# BL808 register map
File version: 0.1
Registers are access not given, no defined reset value unless marked. A register's access mark holds for its fields unless they carry their own. Offsets are from the block's base; [hi:lo] are bit positions; {n}, {i} and the like mark numbered series.

## CCI
Base 0x20008000
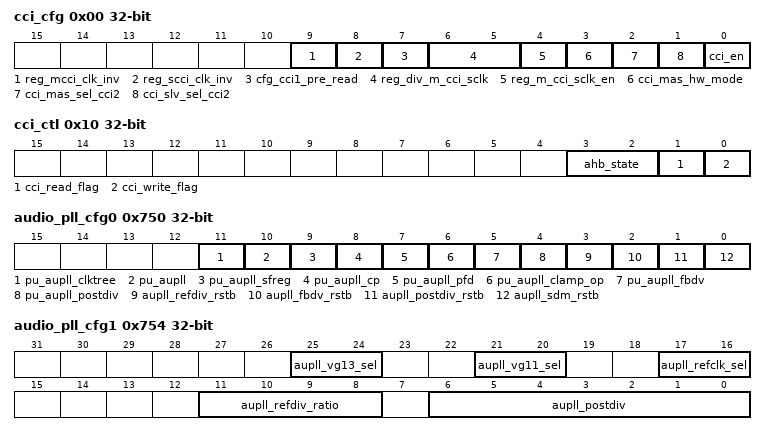
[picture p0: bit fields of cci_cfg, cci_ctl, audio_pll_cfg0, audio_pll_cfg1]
0x00 cci_cfg
  [9] reg_mcci_clk_inv rw, [8] reg_scci_clk_inv rw, [7] cfg_cci1_pre_read rw, [6:5] reg_div_m_cci_sclk rw, [4] reg_m_cci_sclk_en rw, [3] cci_mas_hw_mode rw, [2] cci_mas_sel_cci2 rw, [1] cci_slv_sel_cci2 rw, [0] cci_en rw
0x04 cci_addr rw
  [31:0] apb_cci_addr
0x08 cci_wdata rw
  [31:0] apb_cci_wdata
0x0C cci_rdata ro
  [31:0] apb_cci_rdata
0x10 cci_ctl
  [3:2] ahb_state ro, [1] cci_read_flag ro, [0] cci_write_flag ro
0x750 audio_pll_cfg0
  [11] pu_aupll_clktree rw, [10] pu_aupll rw, [9] pu_aupll_sfreg rw, [8] pu_aupll_cp rw, [7] pu_aupll_pfd rw, [6] pu_aupll_clamp_op rw, [5] pu_aupll_fbdv rw, [4] pu_aupll_postdiv rw, [3] aupll_refdiv_rstb rw, [2] aupll_fbdv_rstb rw, [1] aupll_postdiv_rstb rw, [0] aupll_sdm_rstb rw
0x754 audio_pll_cfg1
  [25:24] aupll_vg13_sel rw, [21:20] aupll_vg11_sel rw, [17:16] aupll_refclk_sel rw, [11:8] aupll_refdiv_ratio rw, [6:0] aupll_postdiv rw
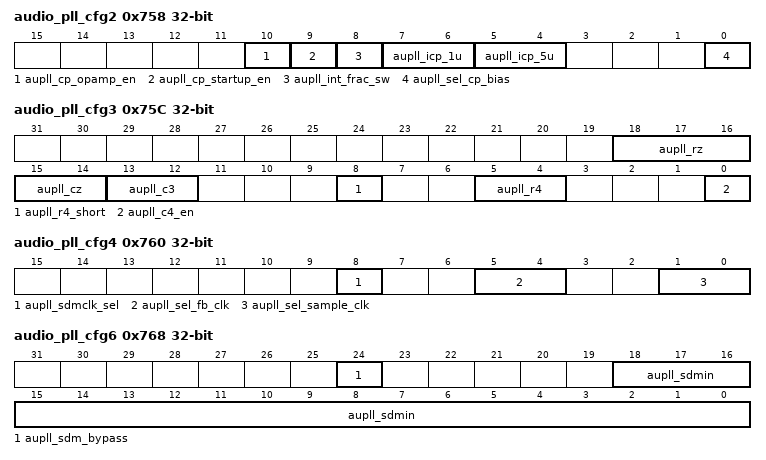
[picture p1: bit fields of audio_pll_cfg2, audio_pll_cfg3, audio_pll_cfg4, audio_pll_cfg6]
0x758 audio_pll_cfg2
  [10] aupll_cp_opamp_en rw, [9] aupll_cp_startup_en rw, [8] aupll_int_frac_sw rw, [7:6] aupll_icp_1u rw, [5:4] aupll_icp_5u rw, [0] aupll_sel_cp_bias rw
0x75C audio_pll_cfg3
  [18:16] aupll_rz rw, [15:14] aupll_cz rw, [13:12] aupll_c3 rw, [8] aupll_r4_short rw, [5:4] aupll_r4 rw, [0] aupll_c4_en rw
0x760 audio_pll_cfg4
  [8] aupll_sdmclk_sel rw, [5:4] aupll_sel_fb_clk rw, [1:0] aupll_sel_sample_clk rw
0x764 audio_pll_cfg5
  [2:0] aupll_vco_speed rw
0x768 audio_pll_cfg6
  [24] aupll_sdm_bypass rw, [18:0] aupll_sdmin rw
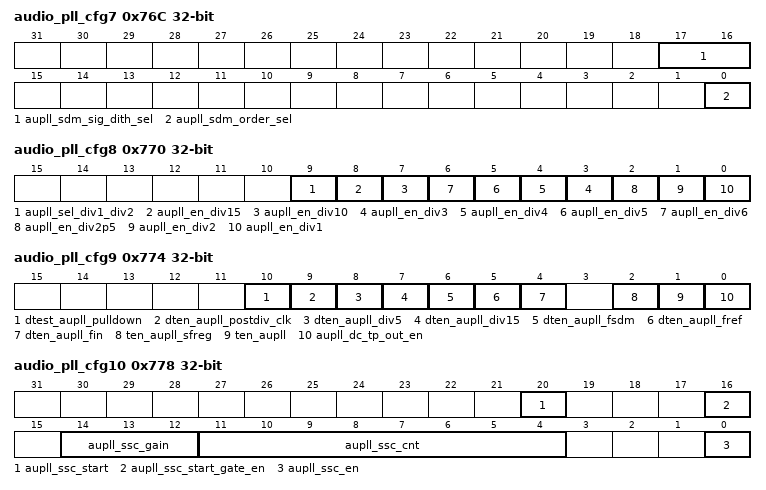
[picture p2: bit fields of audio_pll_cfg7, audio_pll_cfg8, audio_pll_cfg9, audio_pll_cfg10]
0x76C audio_pll_cfg7
  [17:16] aupll_sdm_sig_dith_sel rw, [0] aupll_sdm_order_sel rw
0x770 audio_pll_cfg8
  [9] aupll_sel_div1_div2 rw, [8] aupll_en_div15 rw, [7] aupll_en_div10 rw, [n] aupll_en_div{n} rw (n=3..6), [2] aupll_en_div2p5 rw, [1] aupll_en_div2 rw, [0] aupll_en_div1 rw
0x774 audio_pll_cfg9
  [10] dtest_aupll_pulldown rw, [9] dten_aupll_postdiv_clk rw, [8] dten_aupll_div5 rw, [7] dten_aupll_div15 rw, [6] dten_aupll_fsdm rw, [5] dten_aupll_fref rw, [4] dten_aupll_fin rw, [2] ten_aupll_sfreg rw, [1] ten_aupll rw, [0] aupll_dc_tp_out_en rw
0x778 audio_pll_cfg10
  [20] aupll_ssc_start rw, [16] aupll_ssc_start_gate_en rw, [14:12] aupll_ssc_gain rw, [11:4] aupll_ssc_cnt rw, [0] aupll_ssc_en rw
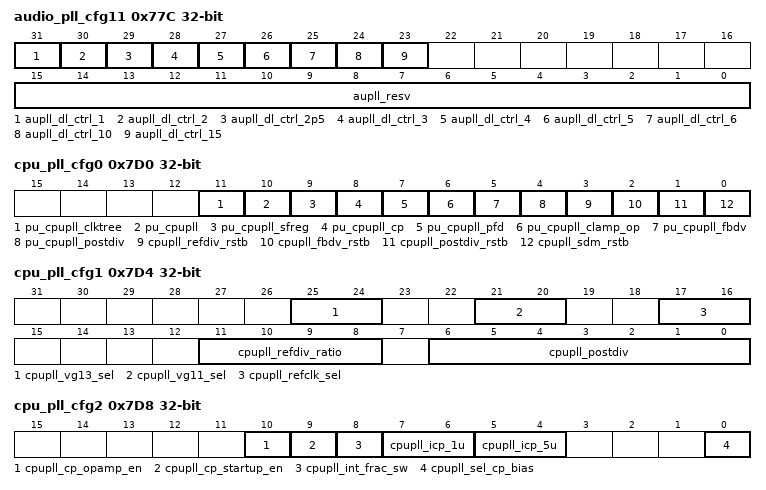
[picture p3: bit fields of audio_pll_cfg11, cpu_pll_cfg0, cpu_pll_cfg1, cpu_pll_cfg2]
0x77C audio_pll_cfg11
  [31] aupll_dl_ctrl_1 rw, [30] aupll_dl_ctrl_2 rw, [29] aupll_dl_ctrl_2p5 rw, [31-n] aupll_dl_ctrl_{n} rw (n=3..6), [24] aupll_dl_ctrl_10 rw, [23] aupll_dl_ctrl_15 rw, [15:0] aupll_resv rw
0x7D0 cpu_pll_cfg0
  [11] pu_cpupll_clktree rw, [10] pu_cpupll rw, [9] pu_cpupll_sfreg rw, [8] pu_cpupll_cp rw, [7] pu_cpupll_pfd rw, [6] pu_cpupll_clamp_op rw, [5] pu_cpupll_fbdv rw, [4] pu_cpupll_postdiv rw, [3] cpupll_refdiv_rstb rw, [2] cpupll_fbdv_rstb rw, [1] cpupll_postdiv_rstb rw, [0] cpupll_sdm_rstb rw
0x7D4 cpu_pll_cfg1
  [25:24] cpupll_vg13_sel rw, [21:20] cpupll_vg11_sel rw, [17:16] cpupll_refclk_sel rw, [11:8] cpupll_refdiv_ratio rw, [6:0] cpupll_postdiv rw
0x7D8 cpu_pll_cfg2
  [10] cpupll_cp_opamp_en rw, [9] cpupll_cp_startup_en rw, [8] cpupll_int_frac_sw rw, [7:6] cpupll_icp_1u rw, [5:4] cpupll_icp_5u rw, [0] cpupll_sel_cp_bias rw
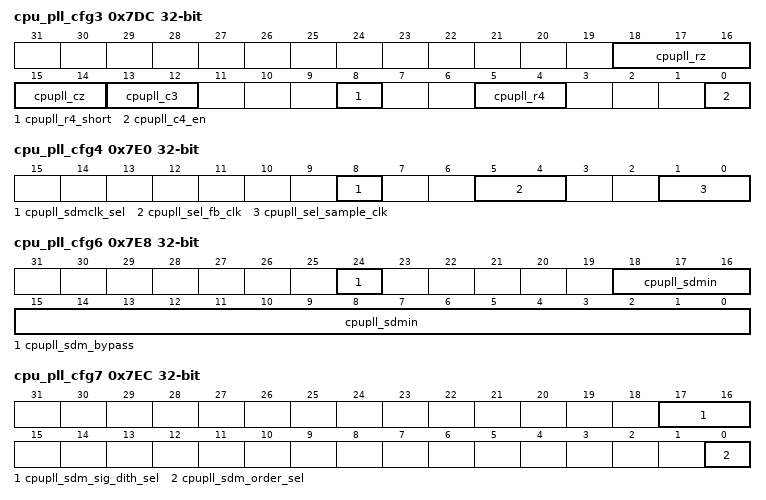
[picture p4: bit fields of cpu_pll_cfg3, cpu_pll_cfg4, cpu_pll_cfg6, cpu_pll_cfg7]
0x7DC cpu_pll_cfg3
  [18:16] cpupll_rz rw, [15:14] cpupll_cz rw, [13:12] cpupll_c3 rw, [8] cpupll_r4_short rw, [5:4] cpupll_r4 rw, [0] cpupll_c4_en rw
0x7E0 cpu_pll_cfg4
  [8] cpupll_sdmclk_sel rw, [5:4] cpupll_sel_fb_clk rw, [1:0] cpupll_sel_sample_clk rw
0x7E4 cpu_pll_cfg5
  [2:0] cpupll_vco_speed rw
0x7E8 cpu_pll_cfg6
  [24] cpupll_sdm_bypass rw, [18:0] cpupll_sdmin rw
0x7EC cpu_pll_cfg7
  [17:16] cpupll_sdm_sig_dith_sel rw, [0] cpupll_sdm_order_sel rw
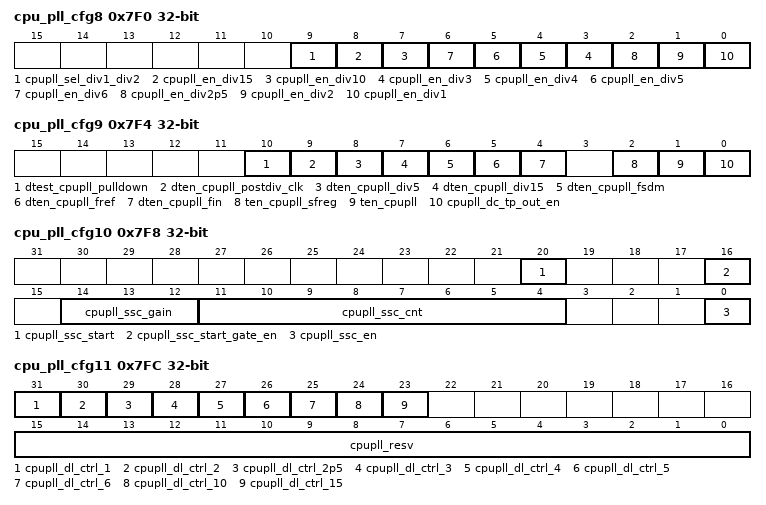
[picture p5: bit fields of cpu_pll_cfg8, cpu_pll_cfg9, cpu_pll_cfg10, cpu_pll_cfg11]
0x7F0 cpu_pll_cfg8
  [9] cpupll_sel_div1_div2 rw, [8] cpupll_en_div15 rw, [7] cpupll_en_div10 rw, [n] cpupll_en_div{n} rw (n=3..6), [2] cpupll_en_div2p5 rw, [1] cpupll_en_div2 rw, [0] cpupll_en_div1 rw
0x7F4 cpu_pll_cfg9
  [10] dtest_cpupll_pulldown rw, [9] dten_cpupll_postdiv_clk rw, [8] dten_cpupll_div5 rw, [7] dten_cpupll_div15 rw, [6] dten_cpupll_fsdm rw, [5] dten_cpupll_fref rw, [4] dten_cpupll_fin rw, [2] ten_cpupll_sfreg rw, [1] ten_cpupll rw, [0] cpupll_dc_tp_out_en rw
0x7F8 cpu_pll_cfg10
  [20] cpupll_ssc_start rw, [16] cpupll_ssc_start_gate_en rw, [14:12] cpupll_ssc_gain rw, [11:4] cpupll_ssc_cnt rw, [0] cpupll_ssc_en rw
0x7FC cpu_pll_cfg11
  [31] cpupll_dl_ctrl_1 rw, [30] cpupll_dl_ctrl_2 rw, [29] cpupll_dl_ctrl_2p5 rw, [31-n] cpupll_dl_ctrl_{n} rw (n=3..6), [24] cpupll_dl_ctrl_10 rw, [23] cpupll_dl_ctrl_15 rw, [15:0] cpupll_resv rw
